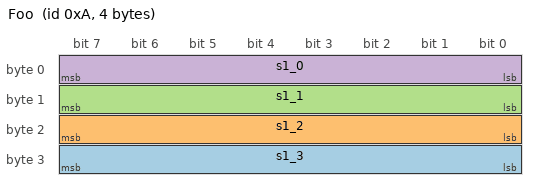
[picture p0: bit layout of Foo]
BO_ 10 Foo: 4 Vector__XXX
 SG_ s1_3 : 24|8@1+ (1,0) [0|0] "m/s^2" Vector__XXX
 SG_ s1_2 : 16|8@1+ (1,0) [0|0] "m/s^2" Vector__XXX
 SG_ s1_1 : 8|8@1+ (1,0) [0|0] "m/s^2" Vector__XXX
 SG_ s1_0 : 0|8@1+ (1,0) [0|0] "m/s^2" Vector__XXX
BO_ 11 Bar: 4 Vector__XXX
 SG_ s1_1 : 16|16@1+ (1,0) [0|0] "" Vector__XXX
 SG_ s1_0 : 0|16@1+ (1,0) [0|0] "" Vector__XXX
